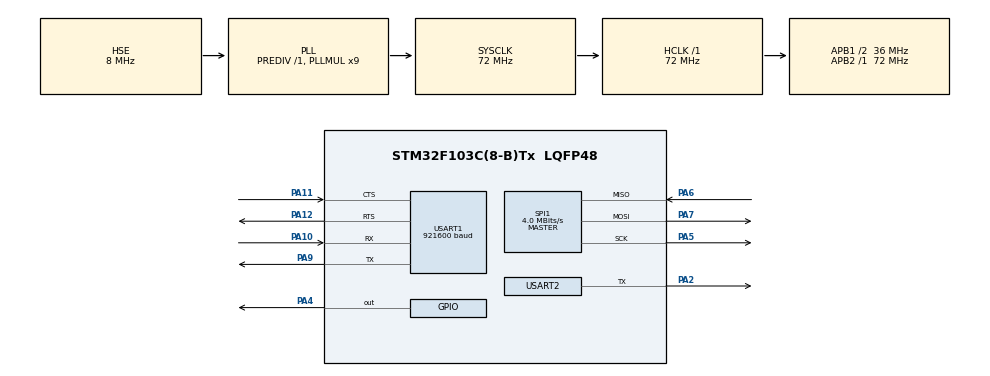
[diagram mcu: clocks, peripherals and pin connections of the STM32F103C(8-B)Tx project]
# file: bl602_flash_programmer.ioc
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Dma.Request0=SPI1_RX
Dma.SPI1_RX.0.Direction=DMA_PERIPH_TO_MEMORY
Dma.SPI1_RX.0.Instance=DMA1_Channel2
Dma.SPI1_RX.0.MemDataAlignment=DMA_MDATAALIGN_BYTE
Dma.SPI1_RX.0.MemInc=DMA_MINC_ENABLE
Dma.SPI1_RX.0.Mode=DMA_NORMAL
Dma.SPI1_RX.0.PeriphDataAlignment=DMA_PDATAALIGN_BYTE
Dma.SPI1_RX.0.PeriphInc=DMA_PINC_DISABLE
Dma.SPI1_RX.0.Priority=DMA_PRIORITY_LOW
Mcu.Family=STM32F1
Mcu.Name=STM32F103C(8-B)Tx
Mcu.Package=LQFP48
NVIC.DMA1_Channel2_IRQn=true\:0\:0\:false\:false\:true\:false\:true\:true
NVIC.PriorityGroup=NVIC_PRIORITYGROUP_4
PA10.Mode=Asynchronous
PA10.Signal=USART1_RX
PA11.Mode=CTS_RTS
PA11.Signal=USART1_CTS
PA12.Mode=CTS_RTS
PA12.Signal=USART1_RTS
PA2.Mode=Asynchronous
PA2.Signal=USART2_TX
PA4.GPIO_ModeDefaultOutputPP=GPIO_MODE_OUTPUT_PP
PA4.GPIO_PuPd=GPIO_PULLUP
PA4.GPIO_Speed=GPIO_SPEED_FREQ_HIGH
PA4.PinState=GPIO_PIN_SET
PA4.Signal=GPIO_Output
PA5.Mode=Full_Duplex_Master
PA5.Signal=SPI1_SCK
PA6.Mode=Full_Duplex_Master
PA6.Signal=SPI1_MISO
PA7.Mode=Full_Duplex_Master
PA7.Signal=SPI1_MOSI
PA9.Mode=Asynchronous
PA9.Signal=USART1_TX
PC14-OSC32_IN.Mode=LSE-External-Clock-Source
PC14-OSC32_IN.Signal=RCC_OSC32_IN
PC15-OSC32_OUT.Mode=LSE-External-Clock-Source
PC15-OSC32_OUT.Signal=RCC_OSC32_OUT
PD0-OSC_IN.Mode=HSE-External-Oscillator
PD0-OSC_IN.Signal=RCC_OSC_IN
PD1-OSC_OUT.Mode=HSE-External-Oscillator
PD1-OSC_OUT.Signal=RCC_OSC_OUT
ProjectManager.HeapSize=0x200
ProjectManager.StackSize=0x400
ProjectManager.TargetToolchain=CMake
RCC.AHBFreq_Value=72000000
RCC.APB1CLKDivider=RCC_HCLK_DIV2
RCC.APB1Freq_Value=36000000
RCC.APB1TimFreq_Value=72000000
RCC.APB2Freq_Value=72000000
RCC.APB2TimFreq_Value=72000000
RCC.HCLKFreq_Value=72000000
RCC.PLLMUL=RCC_PLL_MUL9
RCC.PLLSourceVirtual=RCC_PLLSOURCE_HSE
RCC.RTCClockSelection=RCC_RTCCLKSOURCE_LSI
RCC.SYSCLKFreq_VALUE=72000000
RCC.SYSCLKSource=RCC_SYSCLKSOURCE_PLLCLK
RCC.USBFreq_Value=72000000
SPI1.CLKPhase=SPI_PHASE_2EDGE
SPI1.CLKPolarity=SPI_POLARITY_HIGH
SPI1.CalculateBaudRate=4.0 MBits/s
SPI1.Direction=SPI_DIRECTION_2LINES
SPI1.Mode=SPI_MODE_MASTER
SPI1.VirtualType=VM_MASTER
USART1.BaudRate=921600
USART1.VirtualMode=VM_ASYNC
USART2.BaudRate=921600
USART2.Mode=UART_MODE_TX
USART2.VirtualMode=VM_ASYNC
VP_FATFS_VS_Generic.Mode=User_defined
VP_RTC_VS_RTC_Activate.Mode=RTC_Enabled
VP_SYS_VS_ND.Mode=No_Debug
board=custom

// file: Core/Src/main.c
/* USER CODE BEGIN Header */
/**
  ******************************************************************************
  * @file           : main.c
  * @brief          : Main program body
  ******************************************************************************
  * @attention
  *
  * Copyright (c) 2026 STMicroelectronics.
  * All rights reserved.
  *
  * This software is licensed under terms that can be found in the LICENSE file
  * in the root directory of this software component.
  * If no LICENSE file comes with this software, it is provided AS-IS.
  *
  ******************************************************************************
  */
/* USER CODE END Header */
#include "main.h"
#include "fatfs.h"

/* USER CODE BEGIN Includes */
#include "isp_log.h"
#include "sd_file_demo.h"
#include "bootrom_isp.h"
/* USER CODE END Includes */

RTC_HandleTypeDef hrtc;

SPI_HandleTypeDef hspi1;
DMA_HandleTypeDef hdma_spi1_rx;

UART_HandleTypeDef huart1;
UART_HandleTypeDef huart2;

void SystemClock_Config(void);
static void MX_GPIO_Init(void);
static void MX_DMA_Init(void);
static void MX_RTC_Init(void);
static void MX_USART1_UART_Init(void);
static void MX_USART2_UART_Init(void);
static void MX_SPI1_Init(void);

int main(void)
{

  /* MCU Configuration--------------------------------------------------------*/

  /* Reset of all peripherals, Initializes the Flash interface and the Systick. */
  HAL_Init();

  /* Configure the system clock */
  SystemClock_Config();

  /* Initialize all configured peripherals */
  MX_GPIO_Init();
  MX_DMA_Init();
  MX_USART2_UART_Init();
  MX_USART1_UART_Init();
  MX_RTC_Init();
  MX_SPI1_Init();
  MX_FATFS_Init();
  /* USER CODE BEGIN 2 */
  isp_log_init();
  isp_log_printf("\r\nSTM32F103 BL602 SD ISP flasher\r\n");
  isp_log_printf("HSE 8MHz * PLL9  SYSCLK=%lu Hz\r\n",
                 (unsigned long)HAL_RCC_GetSysClockFreq());
  isp_log_printf("USART2 log 921600 8N1 TX-only  PA2\r\n");
  isp_log_printf("USART1 ISP  921600 8N1  PA9=TX PA10=RX  PA11=DTR(BOOT) PA12=RTS(EN)\r\n");

  sd_isp_flash_run();
  /* USER CODE END 2 */

  /* Infinite loop */
  while (1)
  {

    /* USER CODE BEGIN 3 */
    HAL_Delay(1000);
  }
  /* USER CODE END 3 */
}

void SystemClock_Config(void)
{
  RCC_OscInitTypeDef RCC_OscInitStruct = {0};
  RCC_ClkInitTypeDef RCC_ClkInitStruct = {0};

  /* HSE crystal 8 MHz * PLL9 = 72 MHz. USART1 921600 needs PCLK2 well above 16 MHz. */
  RCC_OscInitStruct.OscillatorType = RCC_OSCILLATORTYPE_HSE | RCC_OSCILLATORTYPE_LSI;
  RCC_OscInitStruct.HSEState = RCC_HSE_ON;
  RCC_OscInitStruct.HSEPredivValue = RCC_HSE_PREDIV_DIV1;
  RCC_OscInitStruct.HSIState = RCC_HSI_ON;
  RCC_OscInitStruct.LSIState = RCC_LSI_ON;
  RCC_OscInitStruct.PLL.PLLState = RCC_PLL_ON;
  RCC_OscInitStruct.PLL.PLLSource = RCC_PLLSOURCE_HSE;
  RCC_OscInitStruct.PLL.PLLMUL = RCC_PLL_MUL9;
  if (HAL_RCC_OscConfig(&RCC_OscInitStruct) != HAL_OK)
  {
    Error_Handler();
  }

  RCC_ClkInitStruct.ClockType = RCC_CLOCKTYPE_HCLK | RCC_CLOCKTYPE_SYSCLK
                              | RCC_CLOCKTYPE_PCLK1 | RCC_CLOCKTYPE_PCLK2;
  RCC_ClkInitStruct.SYSCLKSource = RCC_SYSCLKSOURCE_PLLCLK;
  RCC_ClkInitStruct.AHBCLKDivider = RCC_SYSCLK_DIV1;
  RCC_ClkInitStruct.APB1CLKDivider = RCC_HCLK_DIV2;
  RCC_ClkInitStruct.APB2CLKDivider = RCC_HCLK_DIV1;

  if (HAL_RCC_ClockConfig(&RCC_ClkInitStruct, FLASH_LATENCY_2) != HAL_OK)
  {
    Error_Handler();
  }
}

static void MX_RTC_Init(void)
{

  /** Initialize RTC Only
  */
  hrtc.Instance = RTC;
  hrtc.Init.AsynchPrediv = RTC_AUTO_1_SECOND;
  hrtc.Init.OutPut = RTC_OUTPUTSOURCE_ALARM;
  if (HAL_RTC_Init(&hrtc) != HAL_OK)
  {
    /* USER CODE BEGIN RTC_Init_Error */
    return;
    /* USER CODE END RTC_Init_Error */
  }

}

static void MX_SPI1_Init(void)
{

  /* SPI1 parameter configuration*/
  hspi1.Instance = SPI1;
  hspi1.Init.Mode = SPI_MODE_MASTER;
  hspi1.Init.Direction = SPI_DIRECTION_2LINES;
  hspi1.Init.DataSize = SPI_DATASIZE_8BIT;
  hspi1.Init.CLKPolarity = SPI_POLARITY_LOW;
  hspi1.Init.CLKPhase = SPI_PHASE_1EDGE;
  hspi1.Init.NSS = SPI_NSS_SOFT;
  /* Slow clock for SD init (<=400 kHz). Driver raises it after card init. */
  hspi1.Init.BaudRatePrescaler = SPI_BAUDRATEPRESCALER_256;
  hspi1.Init.FirstBit = SPI_FIRSTBIT_MSB;
  hspi1.Init.TIMode = SPI_TIMODE_DISABLE;
  hspi1.Init.CRCCalculation = SPI_CRCCALCULATION_DISABLE;
  hspi1.Init.CRCPolynomial = 10;
  if (HAL_SPI_Init(&hspi1) != HAL_OK)
  {
    Error_Handler();
  }

}

static void MX_USART1_UART_Init(void)
{

  huart1.Instance = USART1;
  huart1.Init.BaudRate = 921600;
  huart1.Init.WordLength = UART_WORDLENGTH_8B;
  huart1.Init.StopBits = UART_STOPBITS_1;
  huart1.Init.Parity = UART_PARITY_NONE;
  huart1.Init.Mode = UART_MODE_TX_RX;
  huart1.Init.HwFlowCtl = UART_HWCONTROL_NONE;
  huart1.Init.OverSampling = UART_OVERSAMPLING_16;
  if (HAL_UART_Init(&huart1) != HAL_OK)
  {
    Error_Handler();
  }

}

static void MX_USART2_UART_Init(void)
{

  huart2.Instance = USART2;
  huart2.Init.BaudRate = 921600;
  huart2.Init.WordLength = UART_WORDLENGTH_8B;
  huart2.Init.StopBits = UART_STOPBITS_1;
  huart2.Init.Parity = UART_PARITY_NONE;
  huart2.Init.Mode = UART_MODE_TX;
  huart2.Init.HwFlowCtl = UART_HWCONTROL_NONE;
  huart2.Init.OverSampling = UART_OVERSAMPLING_16;
  if (HAL_UART_Init(&huart2) != HAL_OK)
  {
    Error_Handler();
  }

}

static void MX_DMA_Init(void)
{

  /* DMA controller clock enable */
  __HAL_RCC_DMA1_CLK_ENABLE();

  /* DMA interrupt init */
  /* DMA1_Channel2_IRQn interrupt configuration */
  HAL_NVIC_SetPriority(DMA1_Channel2_IRQn, 0, 0);
  HAL_NVIC_EnableIRQ(DMA1_Channel2_IRQn);

}

static void MX_GPIO_Init(void)
{
  GPIO_InitTypeDef GPIO_InitStruct = {0};

  /* GPIO Ports Clock Enable */
  __HAL_RCC_GPIOC_CLK_ENABLE();
  __HAL_RCC_GPIOD_CLK_ENABLE();
  __HAL_RCC_GPIOA_CLK_ENABLE();

  /*Configure GPIO pin Output Level */
  HAL_GPIO_WritePin(GPIOA, GPIO_PIN_4, GPIO_PIN_SET);

  /*Configure GPIO pin : PA4 */
  GPIO_InitStruct.Pin = GPIO_PIN_4;
  GPIO_InitStruct.Mode = GPIO_MODE_OUTPUT_PP;
  GPIO_InitStruct.Pull = GPIO_PULLUP;
  GPIO_InitStruct.Speed = GPIO_SPEED_FREQ_HIGH;
  HAL_GPIO_Init(GPIOA, &GPIO_InitStruct);

}

void Error_Handler(void)
{
  __disable_irq();
  while (1)
  {
  }
}
